# ECM3532 register map
Vendor: EtaCompute; Series: ECM35xx; File version: 1.0.0
CPU: CM3 r1p1, little endian, MPU, no FPU, 3 interrupt priority bits
Registers are 32-bit, read-write, reset 0x0 unless marked. A register's access mark holds for its fields unless they carry their own. Offsets are from the block's base; [hi:lo] are bit positions; 'fields as' and 'values as' point back to an identical list.

## UART0 — The UART Device provides a UART serial port communication peripheral for the chip. It also provides for on-chip loop back with a second uart on the same chip.
Base 0x50020200
Same registers: UART1 0x50020300
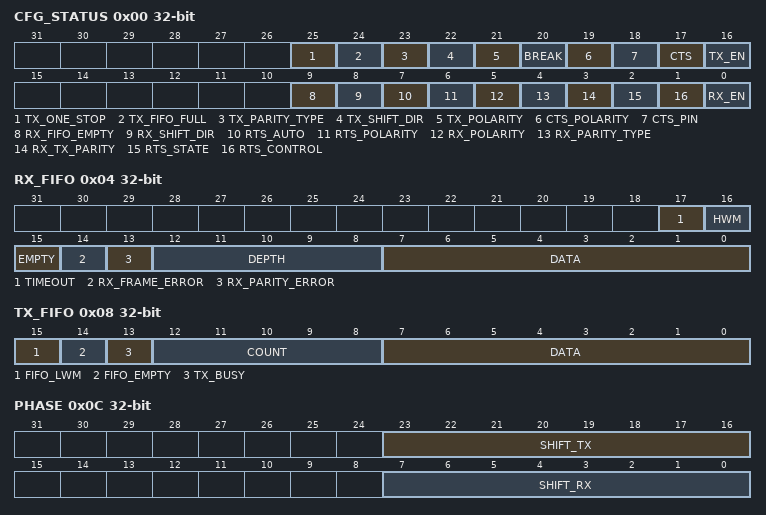
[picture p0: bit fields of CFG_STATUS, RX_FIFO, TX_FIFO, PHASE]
0x00 CFG_STATUS — Configuration and status bits for the UART.
  [25] TX_ONE_STOP — Set to send only one STOP bit, sends two STOP bits by default, if this bit is not set.
    1=SET (Sends one STOP bit.); 0=CLEAR (Sends two STOP bits.)
  [24] TX_FIFO_FULL ro — This bit field returns a 1 if the FIFO count is at 16. This bit is also visible in the GPIO external status register.
  [23] TX_PARITY_TYPE — Set to one to cause the transmitter to generate even parity, if parity is enabled in the CFG_A register.
    1=EVEN (Generate Even Parity.); 0=ODD (Generate Odd Parity.)
  [22] TX_SHIFT_DIR — Writing one to this bit causes the UART to assume MSB first shifting. NOTE: this bit only controls the shift direction for the transmitter side. See the BAUDRATE_HIGH register for a bit that controls the receiver side of the UART.
    1=MSB (Most significant bit first.); 0=LSB (Least significant bit first.)
  [21] TX_POLARITY — This bit defines mark space polarity for the TX pin.
    1=INVERTED (Start equals one stop equals zero and data bit inverted.); 0=NORMAL (Start equals zero, stop equals one.)
  [20] BREAK — Writing one to this bit causes the TX pun to pulled to the break state. This is always the opposite state from the signals idle state.
    1=ENABLE (Enables the transmitter section to use hardware flow control.); 0=STOP (Disables the transmitter section from using hardware flow control.)
  [19] CTS_POLARITY — This bit defines polarity of the CTS pin. Normal polarity for this UART is defined such that a zero/low on the CTS pin means I am clear to send. It appears that it is more common in the industry for the opposite polarity to be used. Thus the default is set to zero.
    1=INVERTED (Clear to send is zero, stop sending is one.); 0=NORMAL (Clear to send is one, stop sending is zero.)
  [18] CTS_PIN ro — This read only bit can be used to determine the state of the CTS input pin. NOTE: The pin value comes on to the chip and goes directly to this status bit without passing through the polarity setting logic.
  [17] CTS — Writing one to this bit enables the use of the CTS input pin to throttle the transmitter section for hardware flow control purposes.
    values as BREAK
  [16] TX_EN — Writing one to this bit enables the transmitter functions. Writing a zero has most of the effects of resetting just the transmitter section.
    1=RUN (Enables the transmitter section to run.); 0=STOP (Turns off the transmitter section.)
  [9] RX_FIFO_EMPTY ro — This bit field returns a 1 if the RX FIFO count is at 0. This bit is also visible in the GPIO external status register.
  [8] RX_SHIFT_DIR — Writing one to this bit causes the UART to assume MSB first shifting. NOTE: this bit only controls the shift direction for the receiver side. See CFG_B for the transmitter shift direction control.
    1=MSB (Shifts data into the receiver MSB first.); 0=LSB (Shifts data into the receiver LSB first.)
  [7] RTS_AUTO — Use automatic hardware algorithm to control the RTS pin state. This is based on RX FIFO high water mark. This is based on RX FIFO high water mark comparator.
    1=ENABLE (Enables automatic RTS flow control in hardware.); 0=DISABLE (Disables automatic RTS flow control in hardware. Use the RTS_STATE value instead.)
  [6] RTS_POLARITY — This bit defines polarity of the RTS pin. Normal polarity for this UART is defined such that a zero/low on the RTS pin means you are clear to send. It appears that it is more common in the industry for the opposite polarity to be used. Thus the default is set to zero.
    1=INVERTED (Request to send is zero, stop sending is one.); 0=NORMAL (Request to send is one, stop sending is zero.)
  [5] RX_POLARITY — This bit defines mark space polarity for the RX pin.
    values as TX_POLARITY
  [4] RX_PARITY_TYPE — Writing one to this bit causes the UART receiver to compute EVEN parity for received frames. NOTE: this bit only controls the parity type for the receiver side. See the BAUDRATE_HIGH register for a bit that controls the transmitter side of the UART.
    1=EVEN (Check for even parity on received frames and check for even parity on received frames.); 0=ODD (Check for odd parity on received frames and check for odd parity on received frames.)
  [3] RX_TX_PARITY — Writing one to this bit causes the UART to insert a parity bit into transmitted frames and to check for parity on received frames.
    1=ENABLE (Enables parity generation and checking.); 0=DISABLE (Disables parity generation and checking.)
  [2] RTS_STATE — The value in this bit field defines the state of the RTS when it is not automatically controlled by the high water mark in the RX FIFO.
    1=RUN (Asserts the RTS signal telling the other end it is free to transmit.); 0=STOP (Deasserts the RTS signal telling the other end to stop transmitting.)
  [1] RTS_CONTROL — Writing one to this bit causes the UART to force the RTS pin to the HALT state. This signals the remote transmitter to stop sending bytes on its TX line. Firmware can use this pin to effect longer HALT times, independent of the normal RTS control mechanism.
    1=FORCE (Force the RTS pin to the HALT state.); 0=FREE (Release the RTS pin to follow either the definition in the RTS_STATE bit or the state defined by the RTS_AUTO pin and the RX FIFO.)
  [0] RX_EN — Writing one to this bit enables the receiver functions. Writing a zero has most of the effects of resetting just the receiver section.
    1=RUN (Enables the receiver section to run.); 0=STOP (Turns off the receiver section.)
0x04 RX_FIFO — Reciever FIFO register.
  [17] TIMEOUT ro — This bit field returns a 1 if the RX FIFO Time Out expired.
  [16] HWM ro — This bit field returns a 1 if the RX FIFO count is above the high water mark.
  [15] EMPTY ro — This bit field returns a 1 if the RX FIFO count is at 0. This bit is also visible in the GPIO external status register.
  [14] RX_FRAME_ERROR — This is not an interrupt status bit. It is an extension of the RX_FIFO_DATA register and obeys the same valid semantics as that register. When a data byte is valid in the RX_FIFO_DATA register then this bit reflects its framing error status. If it is zero then no error is being reported for the data byte in the RX_FIFO_DATA register. If it is a one than an error occurred when that byte was received from the UART_RX pin. Popping the RX FIFO by writing anything to he RX_FIFO_DATA register also advances this bit to correspond to the new value in the RX_FIFO_DATA register.
    1=PRESENT (Indicates a framing error has been detected.); 0=ABSENT (Indicates that no framing error has been detected.)
  [13] RX_PARITY_ERROR — This is not an interrupt status bit. It is an extension of the RX_FIFO_DATA register and obeys the same valid semantics as that register. When a data byte is valid in the RX_FIFO_DATA register then this bit reflects its parity error status. If it is zero then no error is being reported for the data byte in the RX_FIFO_DATA register. If it is a one than an error occurred when that byte was received from the UART_RX pin. Popping the RX FIFO by writing anything to he RX_FIFO_DATA register also advances this bit to correspond to the new value in the RX_FIFO_DATA register.
    1=PRESENT (Indicates a parity error has been detected.); 0=ABSENT (Indicates that no parity error has been detected.)
  [12:8] DEPTH ro — Reads back the current RX FIFO depth.
  [7:0] DATA ro — Reads back the current RX FIFO data at the top of the FIFO.
0x08 TX_FIFO — Transmitter FIFO register.
  [15] FIFO_LWM ro — This bit field returns a 1 if the FIFO count is below its low water mark.
  [14] FIFO_EMPTY ro — This bit field returns a 1 if the FIFO count is at 0.
  [13] TX_BUSY ro — This bit field returns a 1 if the TX FSM is not in its idle state.
  [12:8] COUNT ro — This bit field returns the number of entries currently in the TX FIFO.
  [7:0] DATA — This bit field returns the value of the most recently pushed TX data item.
0x0C PHASE — Any bit with a value of one in this byte will increase the baudrate divider by one count when it is reloaded.
  [23:16] SHIFT_TX — Starting with data bit 0 and proceeding through the first stop bit, each corresponding bit in this bit will increment the reload count by 1 when the count is reloaded.
  [7:0] SHIFT_RX — Starting with data bit 0 and proceeding through the first stop bit, each corresponding bit in this bit will increment the reload count by 1 when the count is reloaded.
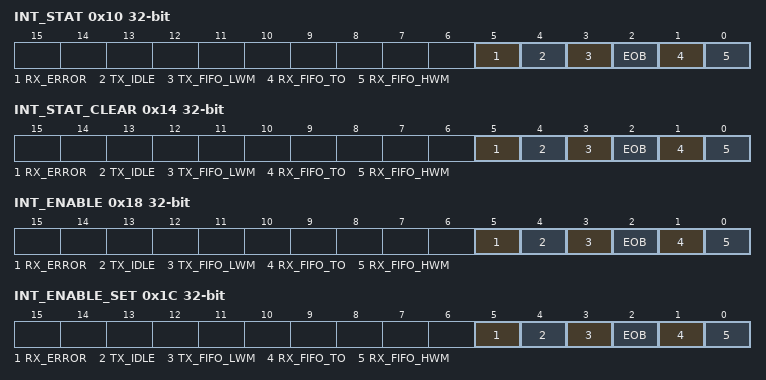
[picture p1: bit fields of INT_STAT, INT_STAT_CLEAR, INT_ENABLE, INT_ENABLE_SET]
0x10 INT_STAT — Interrupt status register.
  [all] fields
    1=PRESENT (Indicates an interrupt has been detected.); 0=ABSENT (Indicates that no interrupt has been detected.)
  [5] RX_ERROR — This interrupt is reported when the receiver has detected at least one parity error or at least one frame error.
  [4] TX_IDLE — This interrupt is reported when the TX FIFO is empty and the TX SERIALIZER is no longer busy. This indicates that the last stop bit of the last byte has left the chip.
  [3] TX_FIFO_LWM — This interrupt is occurs when the TX FIFO count falls below its low water mark.
  [2] EOB — This interrupt is reported when the RX DESERIALIZER detects that a break condition is no longer being signaled on the UART_RX pad.
  [1] RX_FIFO_TO — RX FIFO time out detected. This occurs when the FIFO is not empty for 8 character times. When the FIFO goes non-empty, a timer is started. Everytime a character goes into the FIFO from the UART receiver, the timer is restarted. If it reaches N character times with the FIFO non-empty then this interrupt bit is set.
  [0] RX_FIFO_HWM — RX FIFO is at or above high water marker. Requesting an interrupt for immediate serviceing of the FIFO.
0x14 INT_STAT_CLEAR — Clear corresponding interrupt status register bits.
  [5] RX_ERROR wo — Write a one to clear this interrupt status bit.
  [4] TX_IDLE wo — Write a one to clear this interrupt status bit.
  [3] TX_FIFO_LWM wo — Write a one to clear this interrupt status bit.
  [2] EOB wo — Write a one to clear this interrupt status bit.
  [1] RX_FIFO_TO wo — Write a one to clear this interrupt status bit.
  [0] RX_FIFO_HWM wo — Write a one to clear this interrupt status bit.
0x18 INT_ENABLE — Interrupt enable register.
  [all] fields
    1=ENABLE (Enable this interrupt.); 0=DISABLE (Disable this interrupt.)
  [5] RX_ERROR — Enable this interrupt
  [4] TX_IDLE — Enable this interrupt
  [3] TX_FIFO_LWM — Enable this interrupt
  [2] EOB — Enable this interrupt
  [1] RX_FIFO_TO — Enable this interrupt
  [0] RX_FIFO_HWM — Enable this interrupt
0x1C INT_ENABLE_SET — Interrupt enable register.
  [5] RX_ERROR wo — Write a one to set this interrupt enable bit.
  [4] TX_IDLE wo — Write a one to set this interrupt enable bit.
  [3] TX_FIFO_LWM wo — Write a one to set this interrupt enable bit.
  [2] EOB wo — Write a one to set this interrupt enable bit.
  [1] RX_FIFO_TO wo — Write a one to set this interrupt enable bit.
  [0] RX_FIFO_HWM wo — Write a one to set this interrupt enable bit.
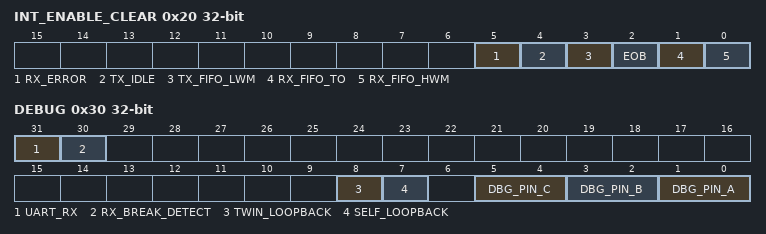
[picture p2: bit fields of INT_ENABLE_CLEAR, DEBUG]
0x20 INT_ENABLE_CLEAR — Interrupt enable register.
  [5] RX_ERROR wo — Write a one to clear this interrupt enable bit.
  [4] TX_IDLE wo — Write a one to clear this interrupt enable bit.
  [3] TX_FIFO_LWM wo — Write a one to clear this interrupt enable bit.
  [2] EOB wo — Write a one to clear this interrupt enable bit.
  [1] RX_FIFO_TO wo — Write a one to clear this interrupt enable bit.
  [0] RX_FIFO_HWM wo — Write a one to clear this interrupt enable bit.
0x24 BAUDRATE — The initial baud rate divisor will be the value set here plus 1.
  [10:0] DIVISOR — 8MHz input clock is divided by DIVISOR+1.
0x28 CONFIG2 — This register holds a clock enable insurance policy bit.
  [0] CLK_ON — Set this bit to one to force the UART clock enable to always remain asserted.
0x30 DEBUG — Debug control register.
  [31] UART_RX ro — This read only bit field provides visibility to the UART RX pin state.
  [30] RX_BREAK_DETECT ro — This read only bit field provides visibility to the UART RX break detector state.
  [8] TWIN_LOOPBACK — Writing one to this bit causes the UART to cross connect its twins signals in a NULL modem configuration with hardware flow controll looped back as well.
    1=ENABLE (Enables loopback.); 0=STOP (Disables loopback.)
  [7] SELF_LOOPBACK — Writing one to this bit causes the UART to cross connect its own signals in a NULL modem configuration with hardware flow controll looped back as well. Setting with TWIN_LOOPBACK produces unpredictable results.
    1=ENABLE (Enables loopback.); 0=STOP (Disables loopback.)
  [5:4] DBG_PIN_C — This bit field selects one of 4 values to present on debug pin C. This pin is presented on GPIO[0] for uart0 and GPIO[3] for uart1.
    0=RX_DATA (Marks the synchronized internal state of UART_RX pin on a GPIO pin.); 1=TX_STEP (Shows the TX step clock on a GPIO pin.); 2=TX_FIFO_LWM (Shows the state of the TX FiFO low water mark status on a GPIO pin.); 3=RX_FIFO_EMPTY (Shows the state of the RX FIFO empty status on a GPIO pin.)
  [3:2] DBG_PIN_B — This bit field selects one of 4 values to present on debug pin B. This pin is presented on GPIO[1] for uart0 and GPIO[4] for uart1.
    0=RX_STEP (Marks the RX step state on a GPIO pin.); 1=TX_STOP (Marks the TX stop bit on a GPIO pin.); 2=TX_FIFO_FULL (Shows the state of the TX FiFO full status.); 3=RX_FIFO_HWM (Shows the state of the RX FIFO high water mark.)
  [1:0] DBG_PIN_A — This bit field selects one of 4 values to present on debug pin A. This pin is presented on GPIO[2] for uart0 and GPIO[5] for uart1.
    0=RX_START (Marks the RX start bit on a GPIO pin.); 1=TX_START (Marks the TX start bit on a GPIO pin.); 2=TX_FIFO_EMPTY (Shows the state of the TX FiFO empty status.); 3=RX_FIFO_TIMEOUT (Indicates when the RX TIME OUT counter is running.)
0x34 DEBUG_READ_ONLY
  [31:0] VALUE ro — A readable test value for testing the bus to the UART.
